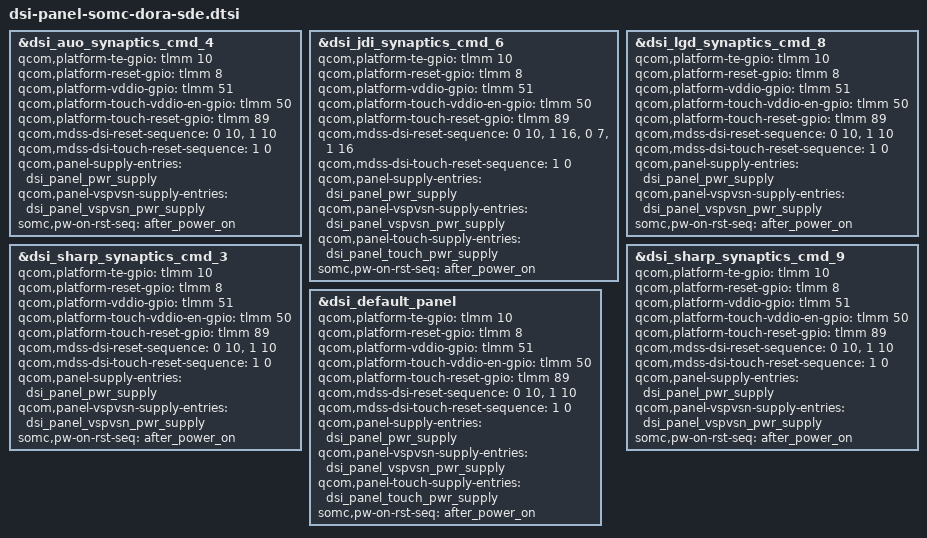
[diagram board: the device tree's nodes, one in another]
/* Copyright (c) 2018, AngeloGioacchino Del Regno <kholk11@gmail.com>
 *
 * This program is free software; you can redistribute it and/or modify
 * it under the terms of the GNU General Public License version 2 and
 * only version 2 as published by the Free Software Foundation.
 *
 * This program is distributed in the hope that it will be useful,
 * but WITHOUT ANY WARRANTY; without even the implied warranty of
 * MERCHANTABILITY or FITNESS FOR A PARTICULAR PURPOSE.  See the
 * GNU General Public License for more details.
 */

&dsi_auo_synaptics_cmd_4 {
		qcom,platform-te-gpio = <&tlmm 10 0>;
		qcom,platform-reset-gpio = <&tlmm 8 0>;
		qcom,platform-vddio-gpio = <&tlmm 51 0>;
		qcom,platform-touch-vddio-en-gpio = <&tlmm 50 0>;
		qcom,platform-touch-reset-gpio = <&tlmm 89 0>;
		qcom,mdss-dsi-reset-sequence = <0 10>, <1 10>;
		qcom,mdss-dsi-touch-reset-sequence = <1 0>;
		qcom,panel-supply-entries = <&dsi_panel_pwr_supply>;
		qcom,panel-vspvsn-supply-entries = <&dsi_panel_vspvsn_pwr_supply>;
		somc,pw-on-rst-seq = "after_power_on";
};

&dsi_jdi_synaptics_cmd_6 {
		qcom,platform-te-gpio = <&tlmm 10 0>;
		qcom,platform-reset-gpio = <&tlmm 8 0>;
		qcom,platform-vddio-gpio = <&tlmm 51 0>;
		qcom,platform-touch-vddio-en-gpio = <&tlmm 50 0>;
		qcom,platform-touch-reset-gpio = <&tlmm 89 0>;
		qcom,mdss-dsi-reset-sequence = <0 10>, <1 16>, <0 7>, <1 16>;
		qcom,mdss-dsi-touch-reset-sequence = <1 0>;
		qcom,panel-supply-entries = <&dsi_panel_pwr_supply>;
		qcom,panel-vspvsn-supply-entries = <&dsi_panel_vspvsn_pwr_supply>;
		qcom,panel-touch-supply-entries = <&dsi_panel_touch_pwr_supply>;
		somc,pw-on-rst-seq = "after_power_on";
};

&dsi_lgd_synaptics_cmd_8 {
		qcom,platform-te-gpio = <&tlmm 10 0>;
		qcom,platform-reset-gpio = <&tlmm 8 0>;
		qcom,platform-vddio-gpio = <&tlmm 51 0>;
		qcom,platform-touch-vddio-en-gpio = <&tlmm 50 0>;
		qcom,platform-touch-reset-gpio = <&tlmm 89 0>;
		qcom,mdss-dsi-reset-sequence = <0 10>, <1 10>;
		qcom,mdss-dsi-touch-reset-sequence = <1 0>;
		qcom,panel-supply-entries = <&dsi_panel_pwr_supply>;
		qcom,panel-vspvsn-supply-entries = <&dsi_panel_vspvsn_pwr_supply>;
		somc,pw-on-rst-seq = "after_power_on";
};

&dsi_sharp_synaptics_cmd_3 {
		qcom,platform-te-gpio = <&tlmm 10 0>;
		qcom,platform-reset-gpio = <&tlmm 8 0>;
		qcom,platform-vddio-gpio = <&tlmm 51 0>;
		qcom,platform-touch-vddio-en-gpio = <&tlmm 50 0>;
		qcom,platform-touch-reset-gpio = <&tlmm 89 0>;
		qcom,mdss-dsi-reset-sequence = <0 10>, <1 10>;
		qcom,mdss-dsi-touch-reset-sequence = <1 0>;
		qcom,panel-supply-entries = <&dsi_panel_pwr_supply>;
		qcom,panel-vspvsn-supply-entries = <&dsi_panel_vspvsn_pwr_supply>;
		somc,pw-on-rst-seq = "after_power_on";
};

&dsi_sharp_synaptics_cmd_9 {
		qcom,platform-te-gpio = <&tlmm 10 0>;
		qcom,platform-reset-gpio = <&tlmm 8 0>;
		qcom,platform-vddio-gpio = <&tlmm 51 0>;
		qcom,platform-touch-vddio-en-gpio = <&tlmm 50 0>;
		qcom,platform-touch-reset-gpio = <&tlmm 89 0>;
		qcom,mdss-dsi-reset-sequence = <0 10>, <1 10>;
		qcom,mdss-dsi-touch-reset-sequence = <1 0>;
		qcom,panel-supply-entries = <&dsi_panel_pwr_supply>;
		qcom,panel-vspvsn-supply-entries = <&dsi_panel_vspvsn_pwr_supply>;
		somc,pw-on-rst-seq = "after_power_on";
};

&dsi_default_panel {
		qcom,platform-te-gpio = <&tlmm 10 0>;
		qcom,platform-reset-gpio = <&tlmm 8 0>;
		qcom,platform-vddio-gpio = <&tlmm 51 0>;
		qcom,platform-touch-vddio-en-gpio = <&tlmm 50 0>;
		qcom,platform-touch-reset-gpio = <&tlmm 89 0>;
		qcom,mdss-dsi-reset-sequence = <0 10>, <1 10>;
		qcom,mdss-dsi-touch-reset-sequence = <1 0>;
		qcom,panel-supply-entries = <&dsi_panel_pwr_supply>;
		qcom,panel-vspvsn-supply-entries = <&dsi_panel_vspvsn_pwr_supply>;
		qcom,panel-touch-supply-entries = <&dsi_panel_touch_pwr_supply>;
		somc,pw-on-rst-seq = "after_power_on";
};
